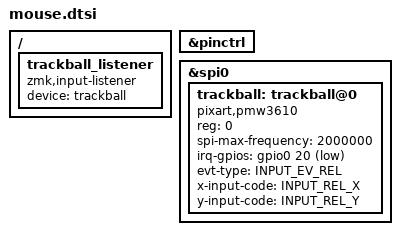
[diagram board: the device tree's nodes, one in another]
#include <dt-bindings/gpio/gpio.h>
#include <zephyr/dt-bindings/pinctrl/nrf-pinctrl.h>
#include <zephyr/dt-bindings/input/input-event-codes.h>

/ {
    trackball_listener: trackball_listener {
        compatible = "zmk,input-listener";
        device = <&trackball>;
    };
};

&pinctrl {
    // ...board-specific SPI pinctrl goes here...
};

&spi0 {
    status = "okay";
    // ...board-specific cs-gpios/pinctrl...
    trackball: trackball@0 {
        status = "okay";
        compatible = "pixart,pmw3610";
        reg = <0>;
        spi-max-frequency = <2000000>;
        irq-gpios = <&gpio0 20 (GPIO_ACTIVE_LOW | GPIO_PULL_UP)>;
        evt-type = <INPUT_EV_REL>;
        x-input-code = <INPUT_REL_X>;
        y-input-code = <INPUT_REL_Y>;
    };
};
